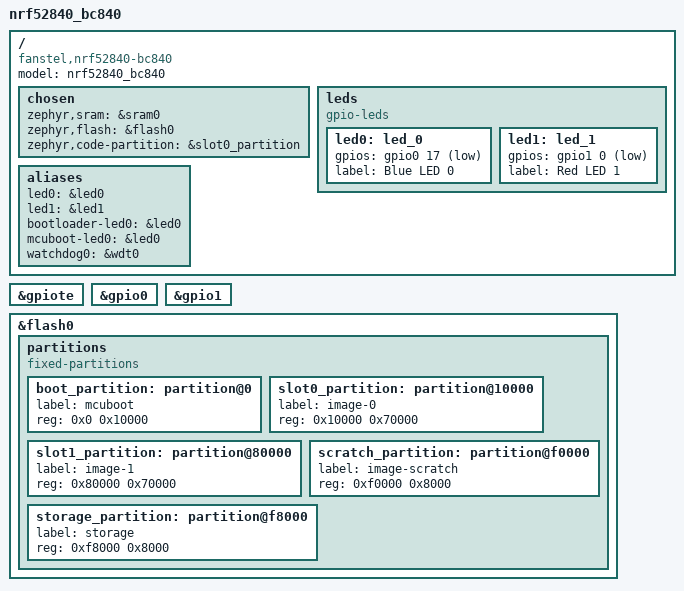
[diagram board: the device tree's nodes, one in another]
// Copyright (c) 2024 Nordic Semiconductor ASA
// SPDX-License-Identifier: Apache-2.0

/dts-v1/;
#include <nordic/nrf52840_qfaa.dtsi>

/ {
	model = "nrf52840_bc840";
	compatible = "fanstel,nrf52840-bc840";

	chosen {
		zephyr,sram = &sram0;
		zephyr,flash = &flash0;
		zephyr,code-partition = &slot0_partition;
	};

	leds {
		compatible = "gpio-leds";
		led0: led_0 {
			gpios = <&gpio0 17 GPIO_ACTIVE_LOW>;
			label = "Blue LED 0";
		};
		led1: led_1 {
			gpios = <&gpio1 0 GPIO_ACTIVE_LOW>;
			label = "Red LED 1";
		};
	};

	aliases {
		led0 = &led0;
		led1 = &led1;
		bootloader-led0 = &led0;
		mcuboot-led0 = &led0;
		watchdog0 = &wdt0;
	};
};

&gpiote {
	status = "okay";
};

&gpio0 {
	status = "okay";
};

&gpio1 {
	status = "okay";
};

&flash0 {
	partitions {
		compatible = "fixed-partitions";
		#address-cells = <1>;
		#size-cells = <1>;

		boot_partition: partition@0 {
			label = "mcuboot";
			reg = <0x0 0x10000>;
		};
		slot0_partition: partition@10000 {
			label = "image-0";
			reg = <0x10000 0x70000>;
		};
		slot1_partition: partition@80000 {
			label = "image-1";
			reg = <0x80000 0x70000>;
		};
		scratch_partition: partition@f0000 {
			label = "image-scratch";
			reg = <0xf0000 0x8000>;
		};
		storage_partition: partition@f8000 {
			label = "storage";
			reg = <0xf8000 0x8000>;
		};
	};
};
